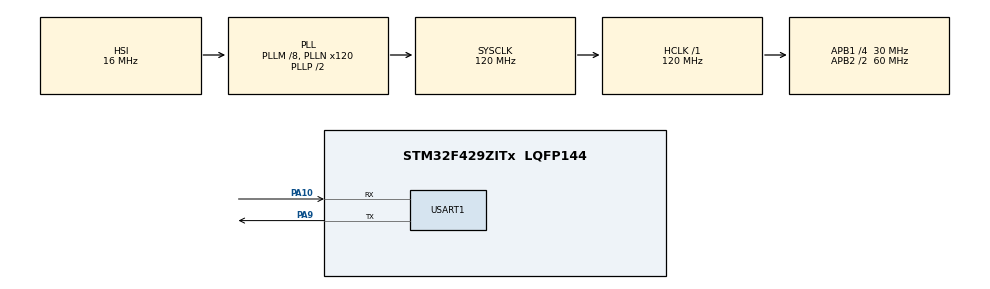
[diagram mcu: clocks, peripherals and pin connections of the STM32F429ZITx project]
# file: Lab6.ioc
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Mcu.Family=STM32F4
Mcu.Name=STM32F429ZITx
Mcu.Package=LQFP144
NVIC.PriorityGroup=NVIC_PRIORITYGROUP_2
NVIC.TIM1_UP_TIM10_IRQn=true\:1\:0\:true\:false\:true\:true\:true
NVIC.TIM2_IRQn=true\:2\:0\:true\:false\:true\:true\:true
PA10.Mode=Asynchronous
PA10.Signal=USART1_RX
PA9.Mode=Asynchronous
PA9.Signal=USART1_TX
ProjectManager.HeapSize=0x200
ProjectManager.StackSize=0x400
ProjectManager.TargetToolchain=STM32CubeIDE
RCC.48MHZClocksFreq_Value=60000000
RCC.AHBFreq_Value=120000000
RCC.APB1CLKDivider=RCC_HCLK_DIV4
RCC.APB1Freq_Value=30000000
RCC.APB1TimFreq_Value=60000000
RCC.APB2CLKDivider=RCC_HCLK_DIV2
RCC.APB2Freq_Value=60000000
RCC.APB2TimFreq_Value=120000000
RCC.CortexFreq_Value=120000000
RCC.HCLKFreq_Value=120000000
RCC.HSE_VALUE=25000000
RCC.HSI_VALUE=16000000
RCC.LSE_VALUE=32768
RCC.PLLM=8
RCC.PLLN=120
RCC.SYSCLKFreq_VALUE=120000000
RCC.SYSCLKSource=RCC_SYSCLKSOURCE_PLLCLK
RCC.VCOOutputFreq_Value=240000000
TIM1.Period=1000-1
TIM1.Prescaler=120-1
TIM2.Period=1000-1
TIM2.Prescaler=24000-1
USART1.VirtualMode=VM_ASYNC
VP_TIM1_VS_ClockSourceINT.Mode=Internal
VP_TIM2_VS_ClockSourceINT.Mode=Internal
board=custom

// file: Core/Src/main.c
/* USER CODE BEGIN Header */
/**
  ******************************************************************************
  * @file           : main.c
  * @brief          : Main program body
  ******************************************************************************
  * @attention
  *
  * <h2><center>&copy; Copyright (c) 2021 STMicroelectronics.
  * All rights reserved.</center></h2>
  *
  * This software component is licensed by ST under BSD 3-Clause license,
  * the "License"; You may not use this file except in compliance with the
  * License. You may obtain a copy of the License at:
  *                        opensource.org/licenses/BSD-3-Clause
  *
  ******************************************************************************
  */
/* USER CODE END Header */
#include "main.h"
#include "tim.h"
#include "usart.h"
#include "gpio.h"

/* USER CODE BEGIN PV */
uint32_t count = 0;
uint32_t waitCheck = 1;
/* USER CODE END PV */

void SystemClock_Config(void);

int main(void)
{

  /* MCU Configuration--------------------------------------------------------*/

  /* Reset of all peripherals, Initializes the Flash interface and the Systick. */
  HAL_Init();

  /* Configure the system clock */
  SystemClock_Config();

  /* Initialize all configured peripherals */
  MX_GPIO_Init();
  MX_TIM1_Init();
  MX_TIM2_Init();
  MX_USART1_UART_Init();
  /* USER CODE BEGIN 2 */
  HAL_TIM_Base_Start_IT(&htim1);
  /* USER CODE END 2 */

  /* Infinite loop */
  while (1)
  {

    /* USER CODE BEGIN 3 */

//	  HAL_UART_Transmit(&huart1, (uint32_t*) "Wait", 4 , 1000);

	  if(waitCheck == 1){
		  waitCheck =0;
		  displayNumber(count);
		  HAL_TIM_Base_Start_IT(&htim2);
	  }
//	  HAL_Delay(400);
  }
  /* USER CODE END 3 */
}

void SystemClock_Config(void)
{
  RCC_OscInitTypeDef RCC_OscInitStruct = {0};
  RCC_ClkInitTypeDef RCC_ClkInitStruct = {0};

  /** Configure the main internal regulator output voltage
  */
  __HAL_RCC_PWR_CLK_ENABLE();
  __HAL_PWR_VOLTAGESCALING_CONFIG(PWR_REGULATOR_VOLTAGE_SCALE3);
  /** Initializes the RCC Oscillators according to the specified parameters
  * in the RCC_OscInitTypeDef structure.
  */
  RCC_OscInitStruct.OscillatorType = RCC_OSCILLATORTYPE_HSI;
  RCC_OscInitStruct.HSIState = RCC_HSI_ON;
  RCC_OscInitStruct.HSICalibrationValue = RCC_HSICALIBRATION_DEFAULT;
  RCC_OscInitStruct.PLL.PLLState = RCC_PLL_ON;
  RCC_OscInitStruct.PLL.PLLSource = RCC_PLLSOURCE_HSI;
  RCC_OscInitStruct.PLL.PLLM = 8;
  RCC_OscInitStruct.PLL.PLLN = 120;
  RCC_OscInitStruct.PLL.PLLP = RCC_PLLP_DIV2;
  RCC_OscInitStruct.PLL.PLLQ = 4;
  if (HAL_RCC_OscConfig(&RCC_OscInitStruct) != HAL_OK)
  {
    Error_Handler();
  }
  /** Initializes the CPU, AHB and APB buses clocks
  */
  RCC_ClkInitStruct.ClockType = RCC_CLOCKTYPE_HCLK|RCC_CLOCKTYPE_SYSCLK
                              |RCC_CLOCKTYPE_PCLK1|RCC_CLOCKTYPE_PCLK2;
  RCC_ClkInitStruct.SYSCLKSource = RCC_SYSCLKSOURCE_PLLCLK;
  RCC_ClkInitStruct.AHBCLKDivider = RCC_SYSCLK_DIV1;
  RCC_ClkInitStruct.APB1CLKDivider = RCC_HCLK_DIV4;
  RCC_ClkInitStruct.APB2CLKDivider = RCC_HCLK_DIV2;

  if (HAL_RCC_ClockConfig(&RCC_ClkInitStruct, FLASH_LATENCY_3) != HAL_OK)
  {
    Error_Handler();
  }
}

/* USER CODE BEGIN 4 */
void displayNumber(uint32_t number)
{
	uint32_t* tmp[50];
	uint32_t* tmp1[50];
	uint32_t sec = number/1000;
	uint32_t min = sec/60;
	uint32_t ShowSec = 0;
	if(min>=60){min -= 60;}
	if(sec>=60){
		ShowSec = sec-(min*60);
	}
	else{
		ShowSec = sec;
	}
	sprintf(tmp, "%02d", ShowSec);
	sprintf(tmp1, "%02d:", min);

	HAL_UART_Transmit(&huart1, (uint32_t*) tmp1, strlen(tmp1), 500);
	HAL_UART_Transmit(&huart1, (uint32_t*) tmp, strlen(tmp), 500);
	HAL_UART_Transmit(&huart1, (uint32_t*) "\r", 4 , 500);
}
/* USER CODE END 4 */

void Error_Handler(void)
{
  __disable_irq();
  while (1)
  {
  }
}

/************************ (C) COPYRIGHT STMicroelectronics *****END OF FILE****/
